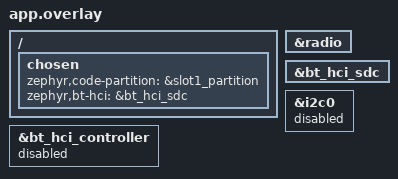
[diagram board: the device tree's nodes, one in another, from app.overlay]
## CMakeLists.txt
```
cmake_minimum_required(VERSION 3.20.0)
list(APPEND BOARD_ROOT ${CMAKE_CURRENT_SOURCE_DIR}/..)
list(APPEND DTS_ROOT ${CMAKE_CURRENT_SOURCE_DIR}/..)
find_package(Zephyr REQUIRED HINTS $ENV{ZEPHYR_BASE})
project(cadence_ble_loader)
target_sources(app PRIVATE src/main.c)
```

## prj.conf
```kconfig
CONFIG_BT=y
CONFIG_BT_PERIPHERAL=y
CONFIG_BT_LL_SOFTDEVICE=y
CONFIG_BT_DEVICE_NAME="CadenceDFU"
CONFIG_BT_MAX_CONN=1
CONFIG_BT_L2CAP_TX_MTU=247
CONFIG_BT_BUF_ACL_RX_SIZE=251
CONFIG_BT_BUF_ACL_TX_SIZE=251
CONFIG_BT_CTLR_DATA_LENGTH_MAX=251

CONFIG_FLASH=y
CONFIG_FLASH_MAP=y
CONFIG_STREAM_FLASH=y
CONFIG_IMG_MANAGER=y
CONFIG_IMG_ERASE_PROGRESSIVELY=y
CONFIG_MCUMGR=y
CONFIG_MCUMGR_MGMT_NOTIFICATION_HOOKS=y
CONFIG_MCUMGR_SMP_COMMAND_STATUS_HOOKS=y
CONFIG_ZCBOR=y
CONFIG_CRC=y
CONFIG_MCUMGR_GRP_IMG=y
CONFIG_MCUMGR_GRP_OS=y
CONFIG_MCUMGR_GRP_OS_BOOTLOADER_INFO=y
CONFIG_MCUMGR_TRANSPORT_BT=y
CONFIG_MCUMGR_TRANSPORT_BT_REASSEMBLY=y
CONFIG_MCUMGR_TRANSPORT_BT_CONN_PARAM_CONTROL=y
CONFIG_MCUMGR_TRANSPORT_NETBUF_SIZE=512
CONFIG_MCUMGR_TRANSPORT_WORKQUEUE_STACK_SIZE=3072
CONFIG_SYSTEM_WORKQUEUE_STACK_SIZE=2048
CONFIG_MAIN_STACK_SIZE=2048
CONFIG_FPROTECT=y
CONFIG_SIZE_OPTIMIZATIONS=y
CONFIG_SERIAL=n
CONFIG_CONSOLE=n
CONFIG_UART_CONSOLE=n
CONFIG_PRINTK=n
CONFIG_BOOT_BANNER=n
CONFIG_NCS_BOOT_BANNER=n
CONFIG_LOG=n
CONFIG_I2C=n
```

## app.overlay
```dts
/ {
	chosen {
		zephyr,code-partition = &slot1_partition;
		zephyr,bt-hci = &bt_hci_sdc;
	};
};
&radio { status = "okay"; };
&bt_hci_sdc { status = "okay"; };
&bt_hci_controller { status = "disabled"; };
&i2c0 { status = "disabled"; };
```

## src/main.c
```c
#include <zephyr/kernel.h>
#include <zephyr/bluetooth/bluetooth.h>
#include <zephyr/bluetooth/conn.h>
#include <zephyr/mgmt/mcumgr/transport/smp_bt.h>
#include <zephyr/mgmt/mcumgr/mgmt/callbacks.h>
#include <zephyr/devicetree.h>
#include <fprotect.h>

static const struct bt_data ad[] = {
	BT_DATA_BYTES(BT_DATA_FLAGS, BT_LE_AD_GENERAL | BT_LE_AD_NO_BREDR),
	BT_DATA_BYTES(BT_DATA_UUID128_ALL, SMP_BT_SVC_UUID_VAL),
};
static const struct bt_data sd[] = {
	BT_DATA(BT_DATA_NAME_COMPLETE, CONFIG_BT_DEVICE_NAME,
		sizeof(CONFIG_BT_DEVICE_NAME) - 1),
};

static void advertise(struct k_work *work)
{
	ARG_UNUSED(work);
	(void)bt_le_adv_start(BT_LE_ADV_CONN_FAST_1, ad, ARRAY_SIZE(ad),
			      sd, ARRAY_SIZE(sd));
}
K_WORK_DEFINE(advertising_work, advertise);

static void recycled(void)
{
	k_work_submit(&advertising_work);
}

BT_CONN_CB_DEFINE(callbacks) = {
	.recycled = recycled,
};

static enum mgmt_cb_return command_guard(uint32_t event,
		enum mgmt_cb_return previous, int32_t *rc, uint16_t *group,
		bool *abort_more, void *data, size_t size)
{
	const struct mgmt_evt_op_cmd_arg *command = data;

	ARG_UNUSED(event);
	ARG_UNUSED(group);
	if (previous != MGMT_CB_OK || size != sizeof(*command)) {
		return previous;
	}
	/* Upload already erases progressively. Disable the standalone image
	 * erase command (ID 5), including explicit requests targeting slot1.
	 */
	if (command->group == MGMT_GROUP_ID_IMAGE && command->id == 5) {
		*rc = MGMT_ERR_ENOTSUP;
		*abort_more = true;
		return MGMT_CB_ERROR_RC;
	}
	return MGMT_CB_OK;
}

static struct mgmt_callback command_callback = {
	.callback = command_guard,
	.event_id = MGMT_EVT_OP_CMD_RECV,
};

int main(void)
{
	/* BPROT survives until reset: malformed SMP commands cannot erase Loader,
	 * bootloader or settings. Only the business slot remains writable.
	 */
	/* Internal flash starts at zero on this board. Read the fixed DTS map
	 * directly so the protection code works across both supported SDKs.
	 */
	if (fprotect_area(DT_REG_ADDR(DT_NODELABEL(boot_partition)),
			  DT_REG_SIZE(DT_NODELABEL(boot_partition))) != 0 ||
	    fprotect_area(DT_REG_ADDR(DT_NODELABEL(slot1_partition)),
			  DT_REG_SIZE(DT_NODELABEL(slot1_partition))) != 0 ||
	    fprotect_area(DT_REG_ADDR(DT_NODELABEL(storage_partition)),
			  DT_REG_SIZE(DT_NODELABEL(storage_partition))) != 0) {
		return 0;
	}
	if (bt_enable(NULL) != 0) {
		return 0;
	}
	mgmt_callback_register(&command_callback);
	k_work_submit(&advertising_work);
	return 0;
}
```
